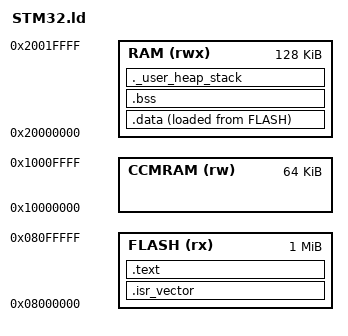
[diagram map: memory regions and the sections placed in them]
/* Linker script for STM32F4xx */
ENTRY(Reset_Handler)

/* Memory layout - adjust for specific STM32 variant */
MEMORY
{
    FLASH (rx)  : ORIGIN = 0x08000000, LENGTH = 1024K
    RAM (rwx)   : ORIGIN = 0x20000000, LENGTH = 128K
    CCMRAM (rw) : ORIGIN = 0x10000000, LENGTH = 64K
}

/* Stack sizes */
_estack = ORIGIN(RAM) + LENGTH(RAM);
_Min_Heap_Size = 0x200;
_Min_Stack_Size = 0x400;

SECTIONS
{
    .isr_vector :
    {
        . = ALIGN(4);
        KEEP(*(.isr_vector))
        . = ALIGN(4);
    } >FLASH

    .text :
    {
        . = ALIGN(4);
        *(.text)
        *(.text*)
        *(.rodata)
        *(.rodata*)
        . = ALIGN(4);
        _etext = .;
    } >FLASH

    .data :
    {
        . = ALIGN(4);
        _sdata = .;
        *(.data)
        *(.data*)
        . = ALIGN(4);
        _edata = .;
    } >RAM AT> FLASH

    _sidata = LOADADDR(.data);

    .bss :
    {
        . = ALIGN(4);
        _sbss = .;
        __bss_start__ = _sbss;
        *(.bss)
        *(.bss*)
        *(COMMON)
        . = ALIGN(4);
        _ebss = .;
        __bss_end__ = _ebss;
    } >RAM

    /* User_heap_stack section */
    ._user_heap_stack :
    {
        . = ALIGN(8);
        PROVIDE ( end = . );
        PROVIDE ( _end = . );
        . = . + _Min_Heap_Size;
        . = . + _Min_Stack_Size;
        . = ALIGN(8);
    } >RAM
}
